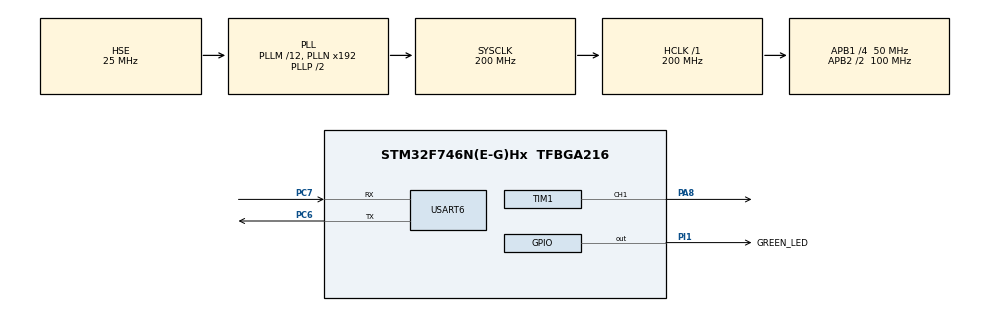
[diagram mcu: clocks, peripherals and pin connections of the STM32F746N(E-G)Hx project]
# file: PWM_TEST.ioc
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Mcu.Family=STM32F7
Mcu.Name=STM32F746N(E-G)Hx
Mcu.Package=TFBGA216
NVIC.PriorityGroup=NVIC_PRIORITYGROUP_4
NVIC.USART6_IRQn=true\:0\:0\:false\:false\:true
PA13.Mode=Serial_Wire
PA13.Signal=SYS_JTMS-SWDIO
PA14.Mode=Serial_Wire
PA14.Signal=SYS_JTCK-SWCLK
PA8.Signal=S_TIM1_CH1
PC6.Mode=Asynchronous
PC6.Signal=USART6_TX
PC7.Mode=Asynchronous
PC7.Signal=USART6_RX
PH0/OSC_IN.Mode=HSE-External-Oscillator
PH0/OSC_IN.Signal=RCC_OSC_IN
PH1/OSC_OUT.Mode=HSE-External-Oscillator
PH1/OSC_OUT.Signal=RCC_OSC_OUT
PI1.GPIO_Label=GREEN_LED
PI1.GPIO_Speed=GPIO_SPEED_FREQ_MEDIUM
PI1.Signal=GPIO_Output
ProjectManager.HeapSize=0x200
ProjectManager.StackSize=0x400
ProjectManager.TargetToolchain=Makefile
RCC.AHBFreq_Value=200000000
RCC.APB1CLKDivider=RCC_HCLK_DIV4
RCC.APB1Freq_Value=50000000
RCC.APB1TimFreq_Value=100000000
RCC.APB2CLKDivider=RCC_HCLK_DIV2
RCC.APB2Freq_Value=100000000
RCC.APB2TimFreq_Value=200000000
RCC.CortexFreq_Value=200000000
RCC.HCLKFreq_Value=200000000
RCC.HSE_VALUE=25000000
RCC.HSI_VALUE=16000000
RCC.LSE_VALUE=32768
RCC.PLLM=12
RCC.PLLSourceVirtual=RCC_PLLSOURCE_HSE
RCC.SYSCLKFreq_VALUE=200000000
RCC.SYSCLKSource=RCC_SYSCLKSOURCE_PLLCLK
RCC.USBFreq_Value=200000000
RCC.VCOOutputFreq_Value=400000000
SH.S_TIM1_CH1.0=TIM1_CH1,PWM Generation1 CH1
TIM1.Channel-PWM\ Generation1\ CH1=TIM_CHANNEL_1
TIM1.Period=10000
TIM1.Prescaler=199
TIM1.Pulse-PWM\ Generation1\ CH1=4000
USART6.VirtualMode-Asynchronous=VM_ASYNC
USART6.WordLength=WORDLENGTH_8B
VP_TIM1_VS_ClockSourceINT.Mode=Internal
board=STM32F746G-DISCO

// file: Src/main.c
/**
  ******************************************************************************
  * File Name          : main.c
  * Description        : Main program body
  ******************************************************************************
  ** This notice applies to any and all portions of this file
  * that are not between comment pairs USER CODE BEGIN and
  * USER CODE END. Other portions of this file, whether
  * inserted by the user or by software development tools
  * are owned by their respective copyright owners.
  *
  * COPYRIGHT(c) 2017 STMicroelectronics
  *
  * Redistribution and use in source and binary forms, with or without modification,
  * are permitted provided that the following conditions are met:
  *   1. Redistributions of source code must retain the above copyright notice,
  *      this list of conditions and the following disclaimer.
  *   2. Redistributions in binary form must reproduce the above copyright notice,
  *      this list of conditions and the following disclaimer in the documentation
  *      and/or other materials provided with the distribution.
  *   3. Neither the name of STMicroelectronics nor the names of its contributors
  *      may be used to endorse or promote products derived from this software
  *      without specific prior written permission.
  *
  * THIS SOFTWARE IS PROVIDED BY THE COPYRIGHT HOLDERS AND CONTRIBUTORS "AS IS"
  * AND ANY EXPRESS OR IMPLIED WARRANTIES, INCLUDING, BUT NOT LIMITED TO, THE
  * IMPLIED WARRANTIES OF MERCHANTABILITY AND FITNESS FOR A PARTICULAR PURPOSE ARE
  * DISCLAIMED. IN NO EVENT SHALL THE COPYRIGHT HOLDER OR CONTRIBUTORS BE LIABLE
  * FOR ANY DIRECT, INDIRECT, INCIDENTAL, SPECIAL, EXEMPLARY, OR CONSEQUENTIAL
  * DAMAGES (INCLUDING, BUT NOT LIMITED TO, PROCUREMENT OF SUBSTITUTE GOODS OR
  * SERVICES; LOSS OF USE, DATA, OR PROFITS; OR BUSINESS INTERRUPTION) HOWEVER
  * CAUSED AND ON ANY THEORY OF LIABILITY, WHETHER IN CONTRACT, STRICT LIABILITY,
  * OR TORT (INCLUDING NEGLIGENCE OR OTHERWISE) ARISING IN ANY WAY OUT OF THE USE
  * OF THIS SOFTWARE, EVEN IF ADVISED OF THE POSSIBILITY OF SUCH DAMAGE.
  *
  ******************************************************************************
  */
#include "main.h"
#include "stm32f7xx_hal.h"

TIM_HandleTypeDef htim1;

UART_HandleTypeDef huart6;

/* USER CODE BEGIN PV */
/* Private variables ---------------------------------------------------------*/
int _write(int file, char *ptr, int len)
{
  int DataIdx;

  for (DataIdx = 0; DataIdx < len; DataIdx++)
  {
     ITM_SendChar( *ptr++ );
  }

  return len;
}
/* USER CODE END PV */

void SystemClock_Config(void);
static void MX_GPIO_Init(void);
static void MX_USART6_UART_Init(void);
static void MX_TIM1_Init(void);

void HAL_TIM_MspPostInit(TIM_HandleTypeDef *htim);

/* USER CODE BEGIN PFP */
/* Private function prototypes -----------------------------------------------*/

/* USER CODE END PFP */

int main(void)
{

  /* MCU Configuration----------------------------------------------------------*/

  /* Reset of all peripherals, Initializes the Flash interface and the Systick. */
  HAL_Init();

  /* Configure the system clock */
  SystemClock_Config();

  /* Initialize all configured peripherals */
  MX_GPIO_Init();
  MX_USART6_UART_Init();
  MX_TIM1_Init();

  /* USER CODE BEGIN 2 */
  HAL_TIM_PWM_Start(&htim1, TIM_CHANNEL_1);
  /* USER CODE END 2 */

  /* Infinite loop */
  while (1)
  {

  }

}

/** System Clock Configuration
*/
void SystemClock_Config(void)
{

  RCC_OscInitTypeDef RCC_OscInitStruct;
  RCC_ClkInitTypeDef RCC_ClkInitStruct;
  RCC_PeriphCLKInitTypeDef PeriphClkInitStruct;

    /**Configure the main internal regulator output voltage
    */
  __HAL_RCC_PWR_CLK_ENABLE();

  __HAL_PWR_VOLTAGESCALING_CONFIG(PWR_REGULATOR_VOLTAGE_SCALE1);

    /**Initializes the CPU, AHB and APB busses clocks
    */
  RCC_OscInitStruct.OscillatorType = RCC_OSCILLATORTYPE_HSE;
  RCC_OscInitStruct.HSEState = RCC_HSE_ON;
  RCC_OscInitStruct.PLL.PLLState = RCC_PLL_ON;
  RCC_OscInitStruct.PLL.PLLSource = RCC_PLLSOURCE_HSE;
  RCC_OscInitStruct.PLL.PLLM = 12;
  RCC_OscInitStruct.PLL.PLLN = 192;
  RCC_OscInitStruct.PLL.PLLP = RCC_PLLP_DIV2;
  RCC_OscInitStruct.PLL.PLLQ = 2;
  if (HAL_RCC_OscConfig(&RCC_OscInitStruct) != HAL_OK)
  {
    _Error_Handler(__FILE__, __LINE__);
  }

    /**Activate the Over-Drive mode
    */
  if (HAL_PWREx_EnableOverDrive() != HAL_OK)
  {
    _Error_Handler(__FILE__, __LINE__);
  }

    /**Initializes the CPU, AHB and APB busses clocks
    */
  RCC_ClkInitStruct.ClockType = RCC_CLOCKTYPE_HCLK|RCC_CLOCKTYPE_SYSCLK
                              |RCC_CLOCKTYPE_PCLK1|RCC_CLOCKTYPE_PCLK2;
  RCC_ClkInitStruct.SYSCLKSource = RCC_SYSCLKSOURCE_PLLCLK;
  RCC_ClkInitStruct.AHBCLKDivider = RCC_SYSCLK_DIV1;
  RCC_ClkInitStruct.APB1CLKDivider = RCC_HCLK_DIV4;
  RCC_ClkInitStruct.APB2CLKDivider = RCC_HCLK_DIV2;

  if (HAL_RCC_ClockConfig(&RCC_ClkInitStruct, FLASH_LATENCY_6) != HAL_OK)
  {
    _Error_Handler(__FILE__, __LINE__);
  }

  PeriphClkInitStruct.PeriphClockSelection = RCC_PERIPHCLK_USART6;
  PeriphClkInitStruct.Usart6ClockSelection = RCC_USART6CLKSOURCE_PCLK2;
  if (HAL_RCCEx_PeriphCLKConfig(&PeriphClkInitStruct) != HAL_OK)
  {
    _Error_Handler(__FILE__, __LINE__);
  }

    /**Configure the Systick interrupt time
    */
  HAL_SYSTICK_Config(HAL_RCC_GetHCLKFreq()/1000);

    /**Configure the Systick
    */
  HAL_SYSTICK_CLKSourceConfig(SYSTICK_CLKSOURCE_HCLK);

  /* SysTick_IRQn interrupt configuration */
  HAL_NVIC_SetPriority(SysTick_IRQn, 0, 0);
}

/* TIM1 init function */
static void MX_TIM1_Init(void)
{

  TIM_ClockConfigTypeDef sClockSourceConfig;
  TIM_MasterConfigTypeDef sMasterConfig;
  TIM_OC_InitTypeDef sConfigOC;
  TIM_BreakDeadTimeConfigTypeDef sBreakDeadTimeConfig;

  htim1.Instance = TIM1;
  htim1.Init.Prescaler = 199;
  htim1.Init.CounterMode = TIM_COUNTERMODE_UP;
  htim1.Init.Period = 10000;
  htim1.Init.ClockDivision = TIM_CLOCKDIVISION_DIV1;
  htim1.Init.RepetitionCounter = 0;
  htim1.Init.AutoReloadPreload = TIM_AUTORELOAD_PRELOAD_DISABLE;
  if (HAL_TIM_Base_Init(&htim1) != HAL_OK)
  {
    _Error_Handler(__FILE__, __LINE__);
  }

  sClockSourceConfig.ClockSource = TIM_CLOCKSOURCE_INTERNAL;
  if (HAL_TIM_ConfigClockSource(&htim1, &sClockSourceConfig) != HAL_OK)
  {
    _Error_Handler(__FILE__, __LINE__);
  }

  if (HAL_TIM_PWM_Init(&htim1) != HAL_OK)
  {
    _Error_Handler(__FILE__, __LINE__);
  }

  sMasterConfig.MasterOutputTrigger = TIM_TRGO_RESET;
  sMasterConfig.MasterOutputTrigger2 = TIM_TRGO2_RESET;
  sMasterConfig.MasterSlaveMode = TIM_MASTERSLAVEMODE_DISABLE;
  if (HAL_TIMEx_MasterConfigSynchronization(&htim1, &sMasterConfig) != HAL_OK)
  {
    _Error_Handler(__FILE__, __LINE__);
  }

  sConfigOC.OCMode = TIM_OCMODE_PWM1;
  sConfigOC.Pulse = 4000;
  sConfigOC.OCPolarity = TIM_OCPOLARITY_HIGH;
  sConfigOC.OCNPolarity = TIM_OCNPOLARITY_HIGH;
  sConfigOC.OCFastMode = TIM_OCFAST_DISABLE;
  sConfigOC.OCIdleState = TIM_OCIDLESTATE_RESET;
  sConfigOC.OCNIdleState = TIM_OCNIDLESTATE_RESET;
  if (HAL_TIM_PWM_ConfigChannel(&htim1, &sConfigOC, TIM_CHANNEL_1) != HAL_OK)
  {
    _Error_Handler(__FILE__, __LINE__);
  }

  sBreakDeadTimeConfig.OffStateRunMode = TIM_OSSR_DISABLE;
  sBreakDeadTimeConfig.OffStateIDLEMode = TIM_OSSI_DISABLE;
  sBreakDeadTimeConfig.LockLevel = TIM_LOCKLEVEL_OFF;
  sBreakDeadTimeConfig.DeadTime = 0;
  sBreakDeadTimeConfig.BreakState = TIM_BREAK_DISABLE;
  sBreakDeadTimeConfig.BreakPolarity = TIM_BREAKPOLARITY_HIGH;
  sBreakDeadTimeConfig.BreakFilter = 0;
  sBreakDeadTimeConfig.Break2State = TIM_BREAK2_DISABLE;
  sBreakDeadTimeConfig.Break2Polarity = TIM_BREAK2POLARITY_HIGH;
  sBreakDeadTimeConfig.Break2Filter = 0;
  sBreakDeadTimeConfig.AutomaticOutput = TIM_AUTOMATICOUTPUT_DISABLE;
  if (HAL_TIMEx_ConfigBreakDeadTime(&htim1, &sBreakDeadTimeConfig) != HAL_OK)
  {
    _Error_Handler(__FILE__, __LINE__);
  }

  HAL_TIM_MspPostInit(&htim1);

}

/* USART6 init function */
static void MX_USART6_UART_Init(void)
{

  huart6.Instance = USART6;
  huart6.Init.BaudRate = 115200;
  huart6.Init.WordLength = UART_WORDLENGTH_8B;
  huart6.Init.StopBits = UART_STOPBITS_1;
  huart6.Init.Parity = UART_PARITY_NONE;
  huart6.Init.Mode = UART_MODE_TX_RX;
  huart6.Init.HwFlowCtl = UART_HWCONTROL_NONE;
  huart6.Init.OverSampling = UART_OVERSAMPLING_16;
  huart6.Init.OneBitSampling = UART_ONE_BIT_SAMPLE_DISABLE;
  huart6.AdvancedInit.AdvFeatureInit = UART_ADVFEATURE_NO_INIT;
  if (HAL_UART_Init(&huart6) != HAL_OK)
  {
    _Error_Handler(__FILE__, __LINE__);
  }

}

/** Configure pins as
        * Analog
        * Input
        * Output
        * EVENT_OUT
        * EXTI
*/
static void MX_GPIO_Init(void)
{

  GPIO_InitTypeDef GPIO_InitStruct;

  /* GPIO Ports Clock Enable */
  __HAL_RCC_GPIOA_CLK_ENABLE();
  __HAL_RCC_GPIOI_CLK_ENABLE();
  __HAL_RCC_GPIOH_CLK_ENABLE();
  __HAL_RCC_GPIOC_CLK_ENABLE();

  /*Configure GPIO pin Output Level */
  HAL_GPIO_WritePin(GREEN_LED_GPIO_Port, GREEN_LED_Pin, GPIO_PIN_RESET);

  /*Configure GPIO pin : GREEN_LED_Pin */
  GPIO_InitStruct.Pin = GREEN_LED_Pin;
  GPIO_InitStruct.Mode = GPIO_MODE_OUTPUT_PP;
  GPIO_InitStruct.Pull = GPIO_NOPULL;
  GPIO_InitStruct.Speed = GPIO_SPEED_FREQ_MEDIUM;
  HAL_GPIO_Init(GREEN_LED_GPIO_Port, &GPIO_InitStruct);

}

void _Error_Handler(char * file, int line)
{
  while(1)
  {
  }
}

/************************ (C) COPYRIGHT STMicroelectronics *****END OF FILE****/
